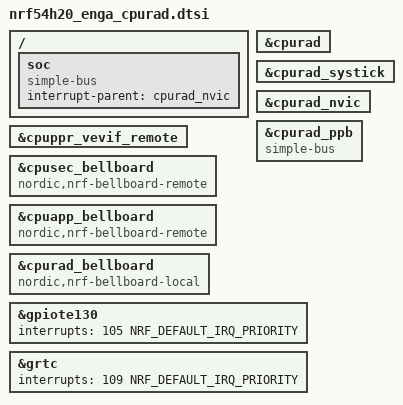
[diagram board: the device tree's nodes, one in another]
/*
 * Copyright (c) 2024 Nordic Semiconductor ASA
 *
 * SPDX-License-Identifier: Apache-2.0
 */

#include <nordic/nrf54h20_enga.dtsi>

cpu: &cpurad {};
systick: &cpurad_systick {};
nvic: &cpurad_nvic {};
cpuppr_vevif: &cpuppr_vevif_remote {};

/delete-node/ &cpuapp;
/delete-node/ &cpuapp_peripherals;
/delete-node/ &cpuapp_ppb;
/delete-node/ &cpuapp_ram0;
/delete-node/ &cpuppr;

/ {
	soc {
		compatible = "simple-bus";
		interrupt-parent = <&cpurad_nvic>;
		ranges;
	};
};

&cpurad_ppb {
	compatible = "simple-bus";
	ranges;
};

&cpusec_bellboard {
	compatible = "nordic,nrf-bellboard-remote";
};

&cpuapp_bellboard {
	compatible = "nordic,nrf-bellboard-remote";
};

&cpurad_bellboard {
	compatible = "nordic,nrf-bellboard-local";
};

&gpiote130 {
	interrupts = <105 NRF_DEFAULT_IRQ_PRIORITY>;
};

&grtc {
	interrupts = <109 NRF_DEFAULT_IRQ_PRIORITY>;
};
